# MDR1986VE8 register map
Vendor: Milandr; Series: ARMCM4; File version: 2.0
CPU: CM4 r0p0, little endian, MPU, FPU, 3 interrupt priority bits
Registers are 32-bit, read-write, reset 0x0 unless marked. A register's access mark holds for its fields unless they carry their own. Offsets are from the block's base; [hi:lo] are bit positions; lines under a group give offsets from that group; {n}, {i} and the like mark numbered series; 'fields as' and 'values as' point back to an identical list.

## MDR_CAN1 — CAN Control
Base 0x40090000
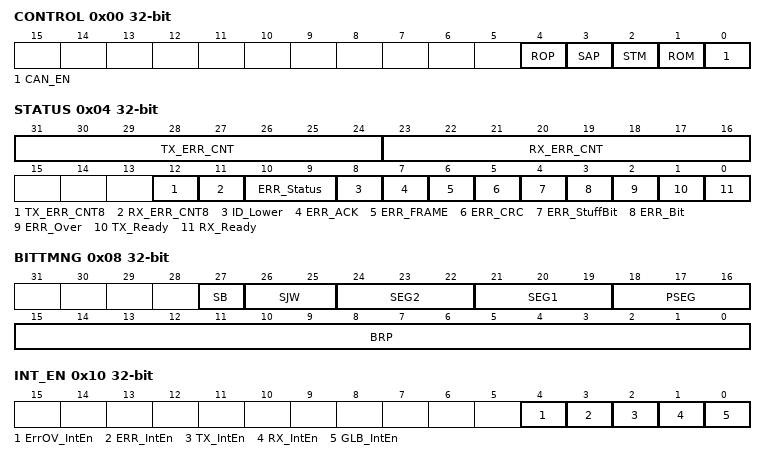
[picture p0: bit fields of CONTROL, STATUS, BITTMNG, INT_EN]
0x00 CONTROL
  [all] fields
    0=Off (Disabled); 1=On (Enabled)
  [4] ROP — Receive Own Packets
  [3] SAP — Send Ack for Own Packets
  [2] STM — Self Test Mode
  [1] ROM — Read Only Mode
  [0] CAN_EN — Enable CAN
0x04 STATUS
  [31:24] TX_ERR_CNT — Tx Error Counter
  [23:16] RX_ERR_CNT — Rx Error Counter
  [12] TX_ERR_CNT8 — TEC > 255, BusOff
    0=Off (Event Inactive); 1=On (Event Active)
  [11] RX_ERR_CNT8 — REC > 255, BusOff
    0=Off (Event Inactive); 1=On (Event Active)
  [10:9] ERR_Status — Eror status
    0=Active mode; 1=Passive (Pasiive error mode); 2=BusOff (Bus Disable)
  [8] ID_Lower — Arbitrage failure
    0=Off (Event Inactive); 1=On (Event Active)
  [7] ERR_ACK — Acknowledge error
    0=Off (Event Inactive); 1=On (Event Active)
  [6] ERR_FRAME — Wrong Frame structure
    0=Off (Event Inactive); 1=On (Event Active)
  [5] ERR_CRC — CRC Error
    0=Off (Event Inactive); 1=On (Event Active)
  [4] ERR_StuffBit — Error in Staff Bit
    0=Off (Event Inactive); 1=On (Event Active)
  [3] ERR_Bit — Error while TX some bit
    0=Off (Event Inactive); 1=On (Event Active)
  [2] ERR_Over — TEC o REC exceeds ERROR_MAX
    0=Off (Event Inactive); 1=On (Event Active)
  [1] TX_Ready — Some buff has data to send
    0=Off (Event Inactive); 1=On (Event Active)
  [0] RX_Ready — Some Buff Data received
    0=Off (Event Inactive); 1=On (Event Active)
0x08 BITTMNG — Bit Timing register
  [27] SB — Line Sampling Count
    0=Single sampling; 1=Triple sampling
  [26:25] SJW — Sync phase deviation
    {v}={v+1}TQ (Delay) (v=0..3)
  [24:22] SEG2 — Delay after line sampling
    {v}={v+1}TQ (Delay) (v=0..7)
  [21:19] SEG1 — Delay before line sampling
    {v}={v+1}TQ (Delay) (v=0..7)
  [18:16] PSEG — Propagation time in TQ
    {v}={v+1}TQ (Delay) (v=0..7)
  [15:0] BRP — Boud Rate Prescaler to TQ
0x10 INT_EN — IRQ Enable
  [all] fields
    0=Disabled (Disable IRQ); 1=Enabled (Enable IRQ)
  [4] ErrOV_IntEn — Enable IRQ of Error Over
  [3] ERR_IntEn — Enable IRQ on Error
  [2] TX_IntEn — Enable IRQ on TX
  [1] RX_IntEn — Enable IRQ on RX
  [0] GLB_IntEn — IRQ Enable Global
0x1C OVER — ERROR_MAX level
  [7:0] ERROR_MAX — Level of TEC or REC errors to OverIRQ
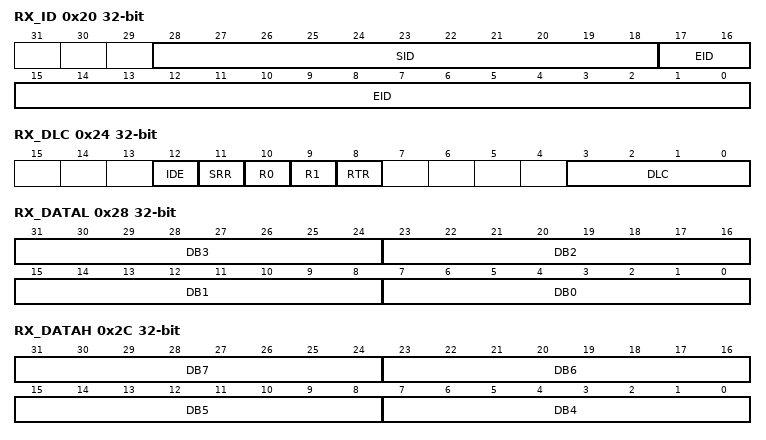
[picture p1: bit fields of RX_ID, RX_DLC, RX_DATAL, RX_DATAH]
0x20 RX_ID (reset mask 0xFFFFFFF) — Last Received ID
  [28:18] SID — Standard frame ID
  [17:0] EID — Extended frame ID
0x24 RX_DLC — Last Received ControlField
  [12] IDE — Frame format
    0=Standard frame; 1=Extended frame
  [11] SRR — Substitute Remote Request
    0=Off (Disabled); 1=On (Enabled)
  [10] R0 — Reserved bit R0
    0=Off (Disabled); 1=On (Enabled)
  [9] R1 — Reserved bit R1
    0=Off (Disabled); 1=On (Enabled)
  [8] RTR — Remote transmission Request
    0=Off (Disabled); 1=On (Enabled)
  [3:0] DLC — Data Length Code
    0=NoData (Normal Operation); {v}=Bytes_{v} (Byte Count) (v=1..8)
0x28 RX_DATAL — Received Byte[0]..Byte[3]
  [8n+7:8n] DB{n} (n=0..3) — Byte {n}
0x2C RX_DATAH — Received Byte[4]..Byte[7]
  [8n-25:8n-32] DB{n} (n=4..7) — Byte {n-4}
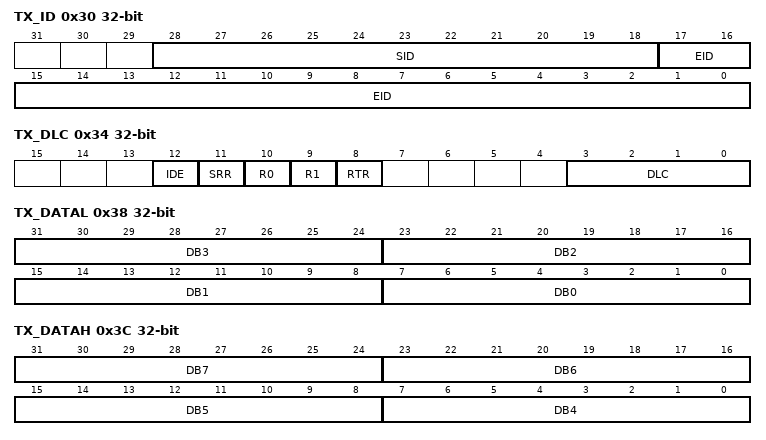
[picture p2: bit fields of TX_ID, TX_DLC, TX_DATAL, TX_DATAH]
0x30 TX_ID (reset mask 0xFFFFFFF) — Last Sent ID
  [28:18] SID — Standard frame ID
  [17:0] EID — Extended frame ID
0x34 TX_DLC — Last Sent ControlField
  fields as RX_DLC
0x38 TX_DATAL — Last Sent Byte[4]..Byte[7]
  [8n+7:8n] DB{n} (n=0..3) — Byte {n}
0x3C TX_DATAH — Last Sent Byte[4]..Byte[7]
  [8n-25:8n-32] DB{n} (n=4..7) — Byte {n-4}
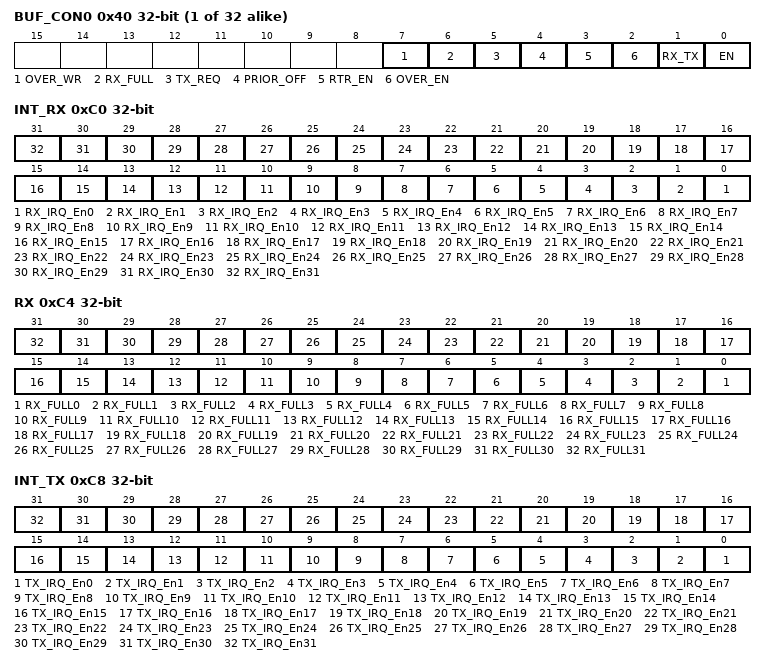
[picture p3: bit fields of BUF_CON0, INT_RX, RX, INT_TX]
{0x40+4i} BUF_CON{i} (i=0..31) — Buffer control
  [7] OVER_WR — Data overwritten
    0=Off (Disabled); 1=On (Enabled)
  [6] RX_FULL — Has new data
    0=Off (Disabled); 1=On (Enabled)
  [5] TX_REQ — Request to send
    0=Off (Disabled); 1=On (Enabled)
  [4] PRIOR_OFF — Send priority Off
    0=Off (Disabled); 1=On (Enabled)
  [3] RTR_EN — RTR ACK enable
    0=Off (Disabled); 1=On (Enabled)
  [2] OVER_EN — Overwrite enable
    0=Off (Disabled); 1=On (Enabled)
  [1] RX_TX — Buffer Direction
    0=TX (Output buffer); 1=RX (Input buffer)
  [0] EN — Buffer enable
    0=Off (Disabled); 1=On (Enabled)
0xC0 INT_RX — Enable Buffs' RX IRQ
  [n] RX_IRQ_En{n} (n=0..31)
    0=Off (IRQ Disabled); 1=On (IRQ Enabled)
0xC4 RX — Buffs' RX_FIFO Full
  [n] RX_FULL{n} (n=0..31)
    0=Empty (No Data); 1=Full (Has Data)
0xC8 INT_TX — Enable Buffs' TX IRQ
  [n] TX_IRQ_En{n} (n=0..31)
    0=Off (IRQ Disabled); 1=On (IRQ Enabled)
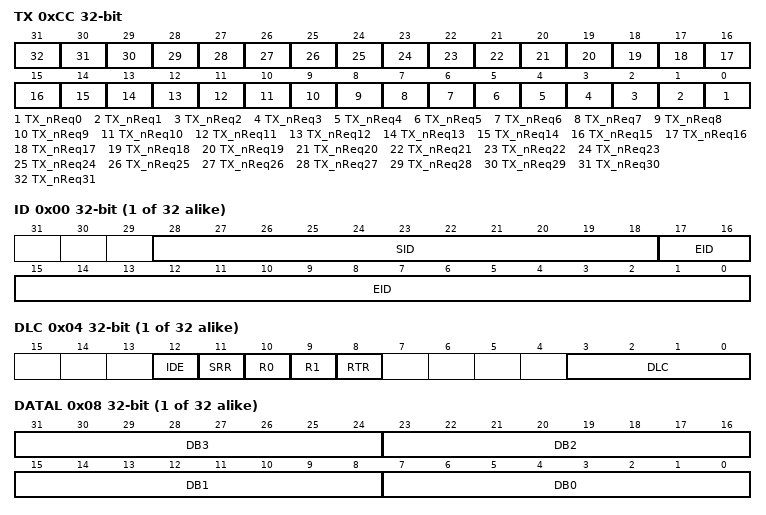
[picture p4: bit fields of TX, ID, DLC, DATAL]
0xCC TX — TX_nReq buffs' state
  [n] TX_nReq{n} (n=0..31)
    0=Active (Tx_Req is active); 1=Off (No req)
{0x200+0x10*i} BUF{i} (i=0..31) group — TX or RX buffer control
  0x00 ID (reset mask 0xFFFFFFF) — packet ID
    [28:18] SID — Standard frame ID
    [17:0] EID — Extended frame ID
  0x04 DLC — ControlField
    fields as RX_DLC
  0x08 DATAL — Byte[4]..Byte[7]
    [8n+7:8n] DB{n} (n=0..3) — Byte {n}
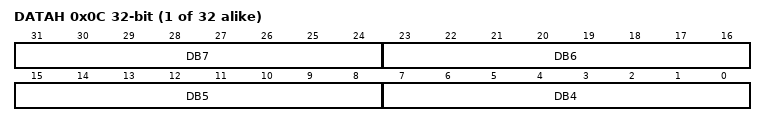
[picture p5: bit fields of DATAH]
  0x0C DATAH — [4]..Byte[7]
    [8n-25:8n-32] DB{n} (n=4..7) — Byte {n-4}
{0x500+8i} FILTER{i} (i=0..31) group — Buffer Receive Filters
  0x00 MASK — MASK for receiver ID
  0x04 FILTER — FILTER for receiver ID

## MDR_DMA — DMA Controler
Base 0xE0042000
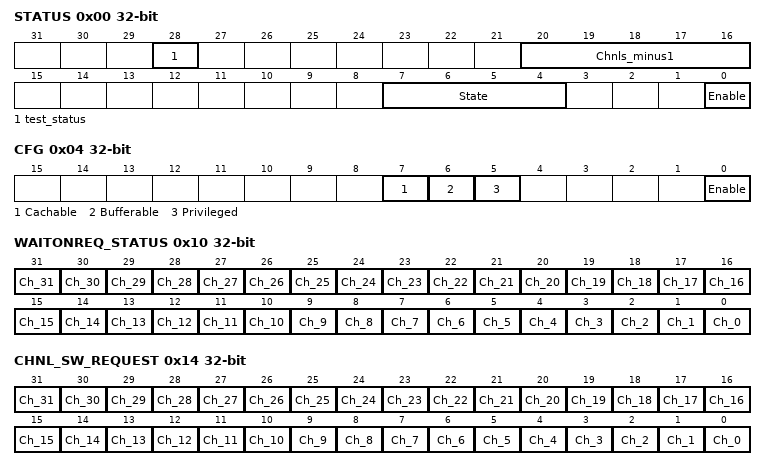
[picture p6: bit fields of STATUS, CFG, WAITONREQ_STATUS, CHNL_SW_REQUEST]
0x00 STATUS ro (reset mask 0xF01F0F01)
  [28] test_status — Test logic availability
    0=Unavailable (Test logic unavailable); 1=Available (Test logic available)
  [20:16] Chnls_minus1 — Channels count
    {v}={v+1}_channels (Channels Count) (v=0..31)
  [7:4] State — Active Operation
    0=Idle state; 1=RD_Ctrl (Reading channel controller data); 2=RD_pSrc (Reading source data end pointer); 3=RD_pDest (Reading destination data end pointer); 4=RD_Data (Reading source data); 5=WR_Data (writing destination data); 6=Wait_Clr (Waiting for DMA request to clear); 7=WR_Ctrl (Writing channel controller data); 8=Stalled transfer; 9=Done transfer; 10=ScatGath (scatter-gather transition)
  [0] Enable — Enable block
    0=Disabled (Block inactive); 1=Enabled (Block active)
0x04 CFG wo — Config register
  [7] Cachable — Cachable AHB bus priority
    0=Off (Inactive); 1=On (Active)
  [6] Bufferable — Bufferable AHB bus priority
    0=Off (Inactive); 1=On (Active)
  [5] Privileged — Privileged AHB bus priority
    0=Off (Inactive); 1=On (Active)
  [0] Enable — Enable block
    0=Disabled (Block inactive); 1=Enabled (Block active)
0x08 CTRL_BASE_PTR — Channel control data base pointer
  [31:10] Addr_Hi — Pointer
0x0C ALT_CTRL_BASE_PTR ro (reset mask 0xFFFFFC00) — Channel alternate control data base pointer
  [31:0] Addr — Pointer
0x10 WAITONREQ_STATUS ro — Channel wait on request status
  [n] Ch_{n} (n=0..31) — Channel Select
    0=Off (Inactive); 1=On (Active)
0x14 CHNL_SW_REQUEST wo write-1-sets — Channel Software Request
  fields as WAITONREQ_STATUS
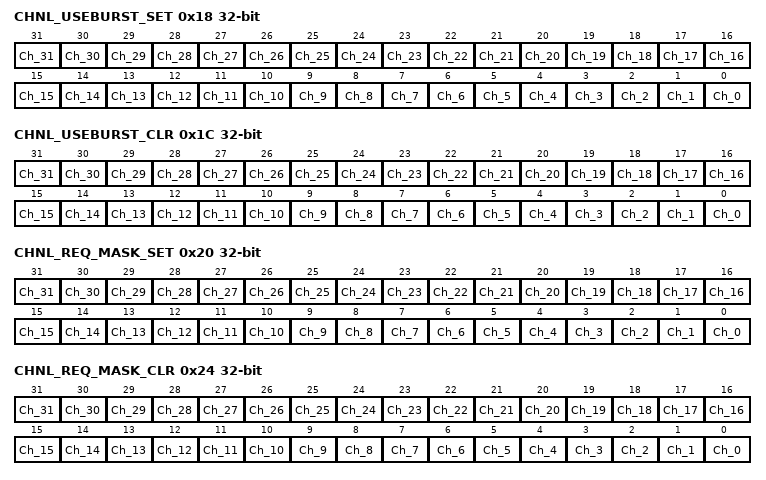
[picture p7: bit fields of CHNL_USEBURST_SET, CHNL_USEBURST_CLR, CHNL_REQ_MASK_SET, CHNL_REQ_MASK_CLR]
0x18 CHNL_USEBURST_SET write-1-sets — Disable SREQ requests
  fields as WAITONREQ_STATUS
0x1C CHNL_USEBURST_CLR wo write-1-clears — Enable SREQ requests
  fields as WAITONREQ_STATUS
0x20 CHNL_REQ_MASK_SET write-1-sets — Disable channel processing
  fields as WAITONREQ_STATUS
0x24 CHNL_REQ_MASK_CLR wo write-1-clears — Enable channel processing
  fields as WAITONREQ_STATUS
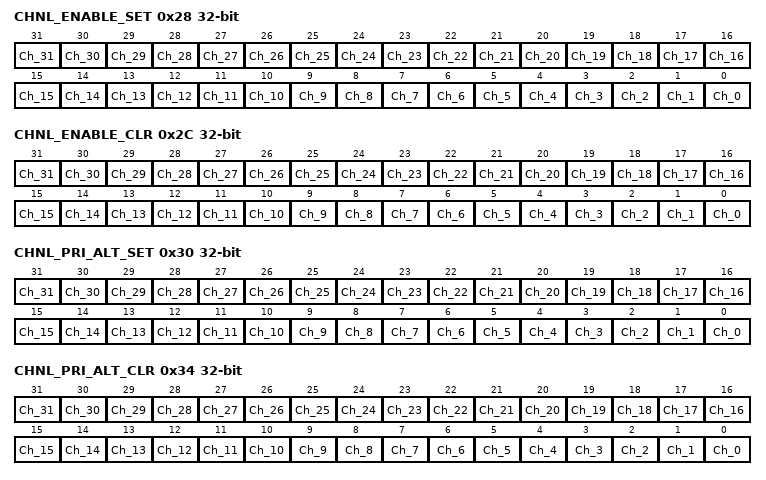
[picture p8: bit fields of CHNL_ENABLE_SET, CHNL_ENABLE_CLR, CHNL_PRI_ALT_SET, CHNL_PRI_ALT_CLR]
0x28 CHNL_ENABLE_SET write-1-sets — Start Channel
  fields as WAITONREQ_STATUS
0x2C CHNL_ENABLE_CLR wo write-1-clears — Stop Channel
  fields as WAITONREQ_STATUS
0x30 CHNL_PRI_ALT_SET write-1-sets — Select Alter Structure
  fields as WAITONREQ_STATUS
0x34 CHNL_PRI_ALT_CLR wo write-1-clears — Select Primary Structure
  fields as WAITONREQ_STATUS
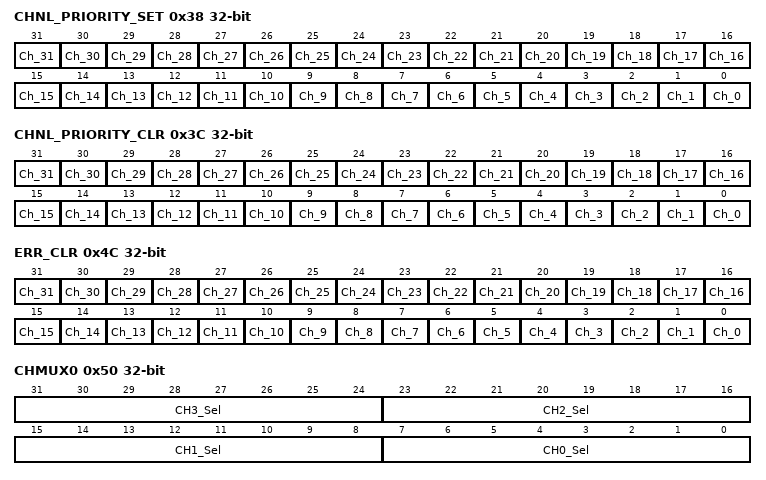
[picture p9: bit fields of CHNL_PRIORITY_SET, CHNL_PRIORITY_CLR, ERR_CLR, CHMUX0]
0x38 CHNL_PRIORITY_SET write-1-sets — Rise up priority to High
  fields as WAITONREQ_STATUS
0x3C CHNL_PRIORITY_CLR wo write-1-clears — Clear Priority to Normal
  fields as WAITONREQ_STATUS
0x4C ERR_CLR write-1-clears — AHB-Lite bus error clear
  fields as WAITONREQ_STATUS
0x50 CHMUX0 — Periph select for DMA channels 0..3
  [8n+7:8n] CH{n}_Sel (n=0..3) — Periph Event for DMA_Channel
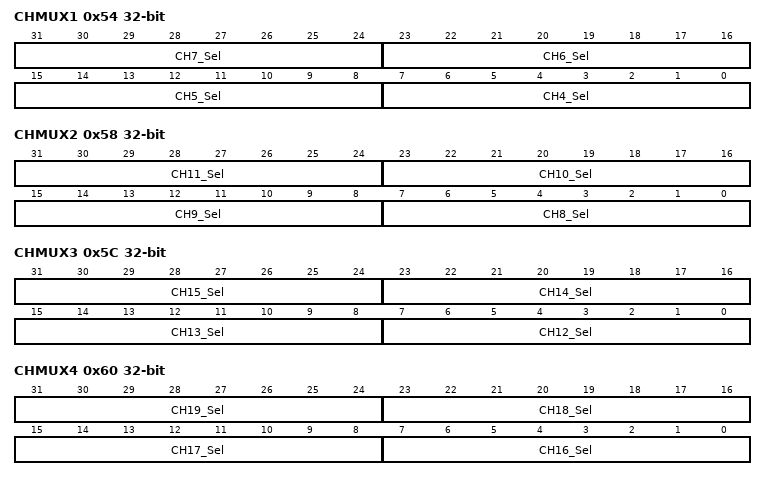
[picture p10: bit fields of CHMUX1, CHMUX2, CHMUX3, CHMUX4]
0x54 CHMUX1 — Periph select for DMA channels 4..7
  [8n-25:8n-32] CH{n}_Sel (n=4..7) — Periph Event for DMA_Channel
0x58 CHMUX2 — Periph select for DMA channels 8..11
  [8n-57:8n-64] CH{n}_Sel (n=8..11) — Periph Event for DMA_Channel
0x5C CHMUX3 — Periph select for DMA channels 12..15
  [8n-89:8n-96] CH{n}_Sel (n=12..15) — Periph Event for DMA_Channel
0x60 CHMUX4 — Periph select for DMA channels 16..19
  [8n-121:8n-128] CH{n}_Sel (n=16..19) — Periph Event for DMA_Channel
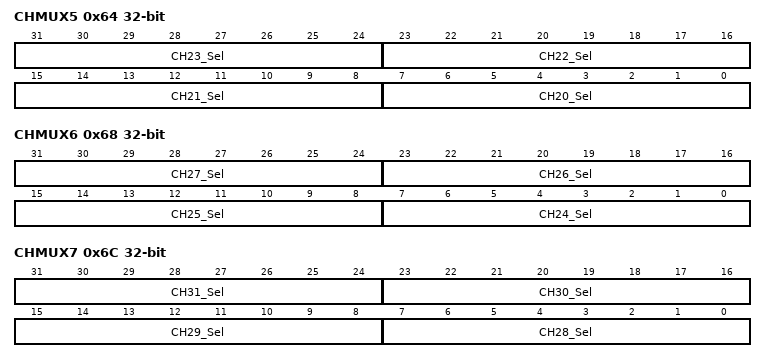
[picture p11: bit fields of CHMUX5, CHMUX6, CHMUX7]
0x64 CHMUX5 — Periph select for DMA channels 20..23
  [8n-153:8n-160] CH{n}_Sel (n=20..23) — Periph Event for DMA_Channel
0x68 CHMUX6 — Periph select for DMA channels 24..27
  [8n-185:8n-192] CH{n}_Sel (n=24..27) — Periph Event for DMA_Channel
0x6C CHMUX7 — Periph select for DMA channels 28..31
  [8n-217:8n-224] CH{n}_Sel (n=28..31) — Periph Event for DMA_Channel
